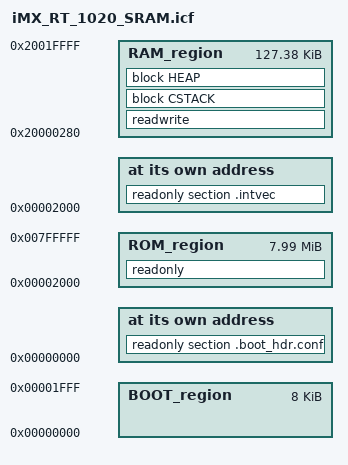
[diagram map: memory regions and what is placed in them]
/* iMX_RT_1020_FlexSPI_NOR.icf - for iMX RT 1020 running from SRAM */
/* 256k SRAM                                                       */
define symbol __ICFEDIT_boot_config__ = 0x00000000;
define symbol __ICFEDIT_ivt__ = 0x00001000;
define symbol __ICFEDIT_boot_data__ = 0x00001020;
define symbol __ICFEDIT_intvec_start__ = 0x00002000;
/*-Memory Regions-*/
define symbol __ICFEDIT_region_BOOT_start__ = 0x00000000;
define symbol __ICFEDIT_region_BOOT_end__   = 0x00001FFF;
define symbol __ICFEDIT_region_ROM_start__  = 0x00002000;
define symbol __ICFEDIT_region_ROM_end__    = 0x007FFFFF;
define symbol __ICFEDIT_region_RAM_start__  = 0x20000280;
define symbol __ICFEDIT_region_RAM_end__    = 0x2001FFFF;
/*-Sizes-*/
define symbol __ICFEDIT_size_cstack__ = 0x0;
define symbol __ICFEDIT_size_heap__   = 0x0;
/**** End of ICF editor section. ###ICF###*/


define memory mem with size = 4G;
define region BOOT_region  = mem:[from __ICFEDIT_region_BOOT_start__ to __ICFEDIT_region_BOOT_end__];
define region ROM_region   = mem:[from __ICFEDIT_region_ROM_start__ to __ICFEDIT_region_ROM_end__];
define region RAM_region   = mem:[from __ICFEDIT_region_RAM_start__ to __ICFEDIT_region_RAM_end__];

define block CSTACK    with alignment = 8, size = __ICFEDIT_size_cstack__   { };
define block HEAP      with alignment = 8, size = __ICFEDIT_size_heap__     { };

initialize by copy { readwrite };
do not initialize  { section .noinit };

place at address mem:__ICFEDIT_boot_config__ { readonly section .boot_hdr.conf };
place at address __ICFEDIT_ivt__ { readonly section .boot_hdr.ivt };
place at address __ICFEDIT_boot_data__ { readonly section .boot_hdr.boot_data };
place at address mem:__ICFEDIT_intvec_start__ { readonly section .intvec };


place in ROM_region   { readonly };
place in RAM_region   { readwrite, block CSTACK, block HEAP };
